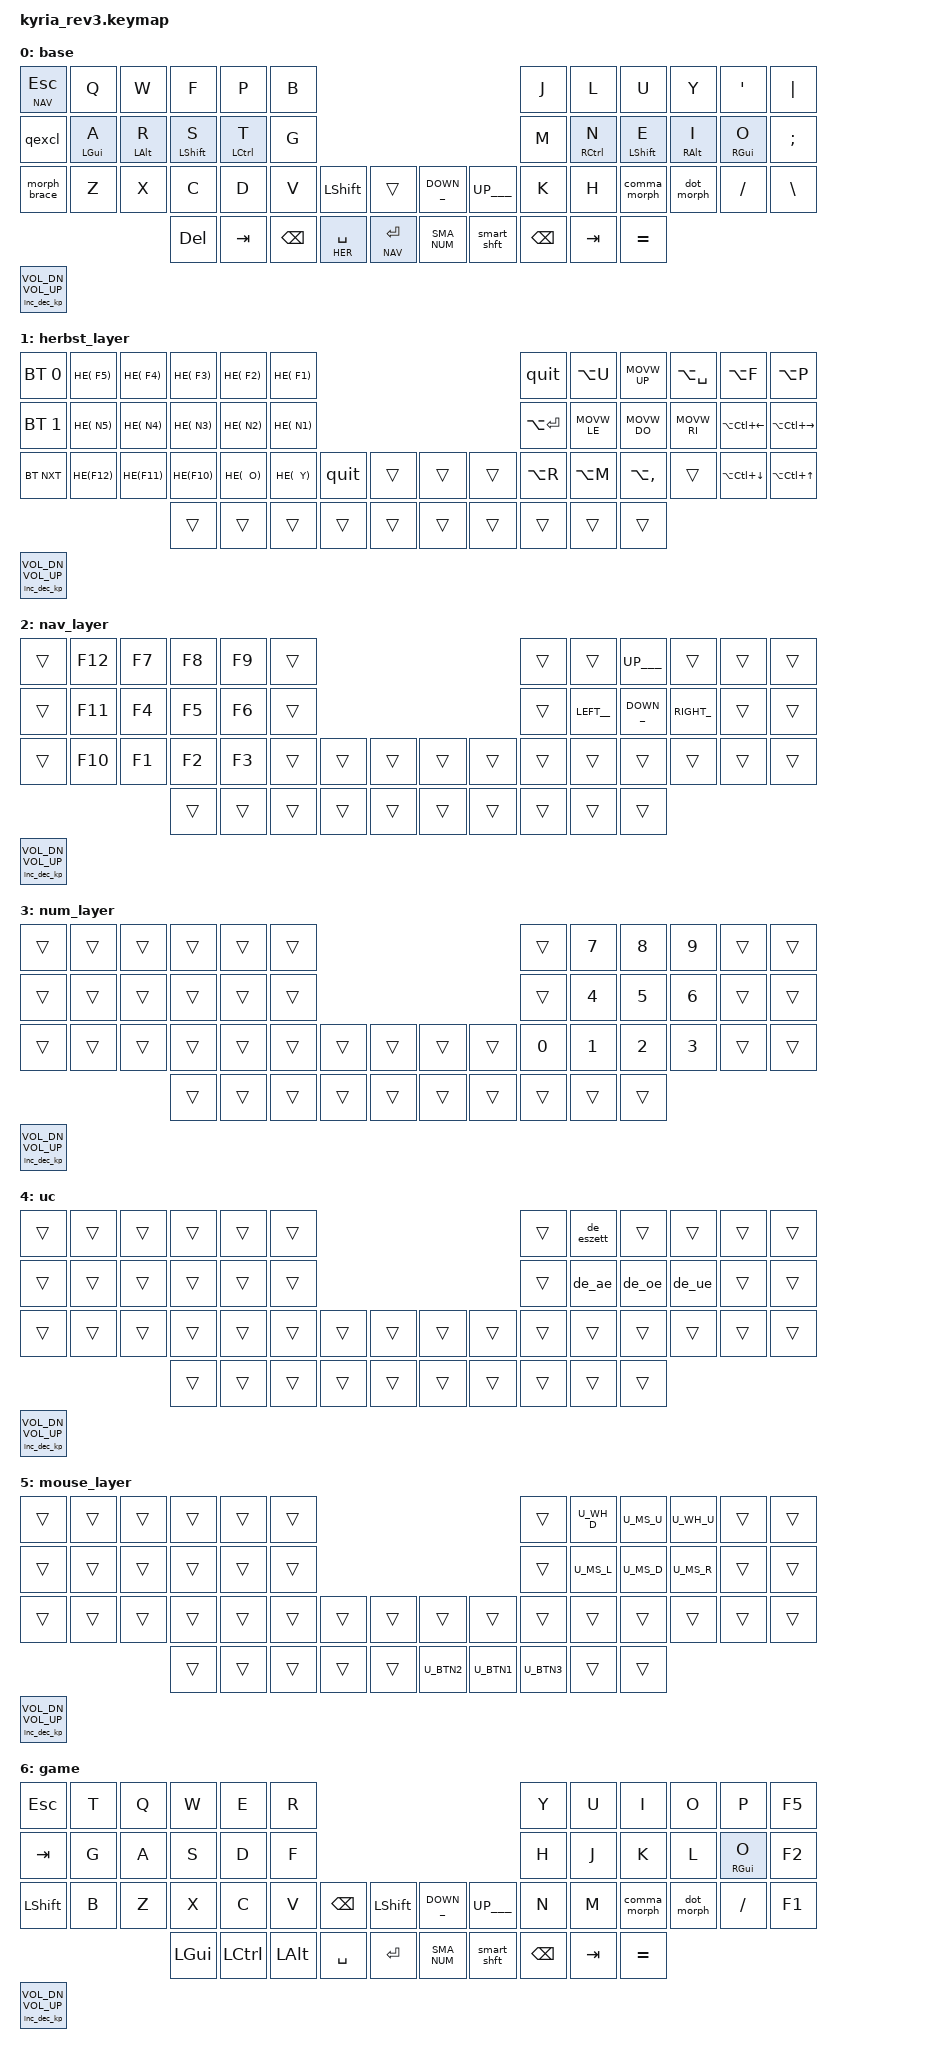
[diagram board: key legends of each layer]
#include <behaviors.dtsi>
#include <dt-bindings/zmk/keys.h>
#include <dt-bindings/zmk/bt.h>
#include <dt-bindings/zmk/outputs.h>
#define HOST_OS 1  // set to 1 for Linux, default is 0 (Windows)
#include "helper.h"
#include "german.dtsi"
#include "keypos_50keys.h"

#define DEF 0
#define HER 1
#define NAV 2
#define NUM 3
#define UC 4
#define MOUSE 5
#define GAME 6

// unused
#define FN 5
#define SYS 6

#include "combos.dtsi"  // requires layer aliases
#include "mouse.dtsi"

/* Global settings */

#define QUICK_TAP_MS 175

&sk {  // sticky-key config
    release-after-ms = <600>;  // release after 0.6s
    quick-release;             // no double capitalization when rolling keys
};

&sl {  // sticky-layer config
    ignore-modifiers;          // allow chording sticky mods & layers
};

&lt {  // layer-tap config
    flavor = "balanced";
    tapping-term-ms = <200>;
    quick-tap-ms = <QUICK_TAP_MS>;
};

&left_encoder { resolution = <2>; };
&right_encoder { resolution = <2>; };


/* Homerow mods */

#define KEYS_L LT0 LT1 LT2 LT3 LT4 LT5 LM0 LM1 LM2 LM3 LM4 RM5 LB0 LB1 LB2 LB3 LB4 LB5 // left-hand keys
#define KEYS_R RT0 RT1 RT2 RT3 RT4 RT5 RM0 RM1 RM2 RM3 RM4 RM5 RB0 RB1 RB2 RB3 RB4 LB5 // right-hand keys
#define THUMBS LH6 LH5 LH4 LH3 LH2 LH1 LH0 RH0 RH1 RH2 RH3 RH4 RH5 RH6

#define MAKE_HRM(NAME, HOLD, TAP, TRIGGER_POS) \
    ZMK_BEHAVIOR(NAME, hold_tap, \
        flavor = "balanced"; \
        tapping-term-ms = <280>; \
        quick-tap-ms = <QUICK_TAP_MS>; \
        global-quick-tap-ms = <150>; \
        bindings = <HOLD>, <TAP>; \
        hold-trigger-key-positions = <TRIGGER_POS>; \
        hold-trigger-on-release; \
    )
MAKE_HRM(hml, &kp, &kp, KEYS_R THUMBS)  // left-hand HRMs
MAKE_HRM(hmr, &kp, &kp, KEYS_L THUMBS)  // right-hand HRMs
MAKE_HRM(hml_repeat, &kp, &key_repeat, KEYS_R THUMBS)  // left-hand HRM for repeat combo

/* Nav cluster */

// long-tap action on hold, short-tap action on all interrupts
#define MT_CORE \
    flavor = "tap-preferred"; \
    tapping-term-ms = <220>; \
    quick-tap-ms = <220>; \
    hold-trigger-key-positions = <0>;

&mt { MT_CORE };
ZMK_BEHAVIOR(mt_home, hold_tap, bindings = <&masked_home>, <&kp>; MT_CORE)
ZMK_BEHAVIOR(mt_end,  hold_tap,  bindings = <&masked_end>, <&kp>; MT_CORE)

#define NAV_LEFT  &mt_home 0   LEFT    // tap: left  | long-tap: beginning of line
#define NAV_RIGHT &mt_end 0    RIGHT   // tap: right | long-tap: end       of line
#define NAV_UP    &mt PAGE_UP UP      // tap: up    | long-tap:
#define NAV_DOWN  &mt PAGE_DOWN  DOWN    // tap: down  | long-tap:
#define NAV_BSPC  &mt LC(BSPC) BSPC    // tap: bspc  | long-tap: delete word backward
#define NAV_DEL   &mt LC(DEL)  DEL     // tap: del   | long-tap: delete word forward

// mask CTRL when holding left/right to avoid accidental jumps to beginning/end of document
#define MASK_MODS(NAME, MODS, BINDING) \
    ZMK_BEHAVIOR(NAME, mod_morph, \
        bindings = <BINDING>, <BINDING>; \
        mods = <MODS>; \
    )
MASK_MODS(masked_home, (MOD_LCTL), &kp HOME)
MASK_MODS(masked_end,  (MOD_LCTL), &kp END)

/* Caps-word, num-word and smart-mouse */

// tap: sticky-shift | shift + tap/ double-tap: caps-word | hold: shift
ZMK_BEHAVIOR(smart_shft, mod_morph,
    bindings = <&sk LSHFT>, <&caps_word>;
    mods = <(MOD_LSFT)>;
)
&caps_word {  // mods deactivate caps-word, requires PR #1441
    /delete-property/ ignore-modifiers;
};

// tap: num-word | double-tap: sticky num-layer | hold: num-layer
#define SMART_NUM &smart_num NUM 0
ZMK_BEHAVIOR(smart_num, hold_tap,
    flavor = "balanced";
    tapping-term-ms = <200>;
    quick-tap-ms = <QUICK_TAP_MS>;
    bindings = <&mo>, <&num_dance>;
)
ZMK_BEHAVIOR(num_dance, tap_dance,
    tapping-term-ms = <200>;
    bindings = <&num_word>, <&sl NUM>;  // reverse this for sticky-num on single tap
)
&num_word {  // num-word, requires PR #1441
    layers = <NUM>;
};

// smart-mouse, requires PR #1366
ZMK_BEHAVIOR(smart_mouse, tri_state,
    bindings = <&tog MOUSE>, <&none>, <&tog MOUSE>;
    ignored-key-positions = <LT1 LT3 RT1 RT2 RT3 RM1 RM2 RM3 RH0 RH1>;
    ignored-layers = <MOUSE>;
)

/* Custom behaviors */

// Alt+Tab swapper, requires PR #1366
ZMK_BEHAVIOR(swapper, tri_state,
    bindings = <&kt LALT>, <&kp TAB>, <&kt LALT>;
    ignored-key-positions = <LT2>;
)

// Sticky layer + sticky shift (workaround for issue #1421)
ZMK_BEHAVIOR(sls, sticky_key,
    release-after-ms = <1000>;
    bindings = <&uc_shift>;
    ignore-modifiers;
)
ZMK_BEHAVIOR(uc_shift, macro,
    wait-ms = <0>;
    tap-ms = <1>;
    bindings = <&macro_press &mo UC &kp LSHFT>
             , <&macro_pause_for_release>
             , <&macro_release &mo UC &kp LSHFT>;
)

// tap: comma | shift + tap: semicolon | ctrl + shift + tap: <
ZMK_BEHAVIOR(comma_morph, mod_morph,
    mods = <(MOD_LSFT|MOD_RSFT)>;
    bindings = <&kp COMMA>, <&comma_inner_morph>;
)
ZMK_BEHAVIOR(comma_inner_morph, mod_morph,
    bindings = <&kp SEMICOLON>, <&kp LESS_THAN>;
    mods = <(MOD_LCTL|MOD_RCTL)>;
)

// tap: dot | shift + tap: colon | ctrl + shift + tap: >
ZMK_BEHAVIOR(dot_morph, mod_morph,
    bindings = <&kp DOT>, <&dot_inner_morph>;
    mods = <(MOD_LSFT|MOD_RSFT)>;
)
ZMK_BEHAVIOR(dot_inner_morph, mod_morph,
    bindings = <&kp COLON>, <&kp GREATER_THAN>;
    mods = <(MOD_LCTL|MOD_RCTL)>;
)

// tap: qmark | shift + tap: excl
ZMK_BEHAVIOR(qexcl, mod_morph,
    bindings = <&kp QMARK>, <&kp EXCL>;
    mods = <(MOD_LSFT|MOD_RSFT)>;
)

// tap: space | shift + tap: dot -> space -> sticky shift | hold: activate layer
ZMK_BEHAVIOR(lt_spc, hold_tap,
    flavor = "balanced";
    tapping-term-ms = <200>;
    quick-tap-ms = <QUICK_TAP_MS>;
    bindings = <&mo>, <&spc_morph>;
)
ZMK_BEHAVIOR(spc_morph, mod_morph,
    bindings = <&kp SPACE>, <&dot_spc>;
    mods = <(MOD_LSFT|MOD_RSFT)>;
)
ZMK_BEHAVIOR(dot_spc, macro,
    wait-ms = <0>;
    tap-ms = <5>;
    bindings = <&kp DOT &kp SPACE &sk LSHFT>;
)

// tap: backspace | lshft + tap: delete | rshft + tap: shift-delete
ZMK_BEHAVIOR(bs_del, mod_morph,
    bindings = <&kp BSPC>, <&kp DEL>;
    mods = <(MOD_LSFT|MOD_RSFT)>;
    keep-mods = <MOD_RSFT>;
)

// tap: copy | double-tap: cut
ZMK_BEHAVIOR(copy_cut, tap_dance,
    tapping-term-ms = <200>;
    bindings = <&kp LC(INS)>, <&kp LC(X)>;
)

// Windows sleep key
ZMK_BEHAVIOR(win_sleep, macro,
    wait-ms = <100>;
    tap-ms = <5>;
    bindings = <&kp LG(X) &kp U &kp S>;
)
// tap: CTRL-C | doubletap: ALT-SHIFT-C
ZMK_BEHAVIOR(quit, tap_dance,
    tapping-term-ms = <200>;
    bindings = <&kp LC(C)>, <&kp LA(LS(C))>;
)

ZMK_BEHAVIOR(morph_parent, mod_morph,
    bindings = <&kp LPAR>, <&kp RPAR>;
    mods = <(MOD_LSFT|MOD_RSFT)>;
)
ZMK_BEHAVIOR(morph_bracket, mod_morph,
  bindings = <&kp LBKT>, <&kp RBKT>;
  mods = <(MOD_LSFT|MOD_RSFT)>;
)
ZMK_BEHAVIOR(morph_brace, mod_morph,
  bindings = <&kp LBRC>, <&kp RBRC>;
  mods = <(MOD_LSFT|MOD_RSFT)>;
)

// misc aliases
#define CANCEL      &kp K_CANCEL             // cancel caps-word, num-word and smart-mouse
#define DSK_PREV    &hmr RSHFT LG(LC(LEFT))  // previous desktop
#define DSK_NEXT    &hmr LALT LG(LC(RIGHT))  // next     desktop
#define VOL_DOWN    &hmr LCTRL C_VOL_DN

/* Keymap */

#define _LEFT__ NAV_LEFT
#define __UP___ NAV_UP
#define _DOWN__ NAV_DOWN
#define _RIGHT_ NAV_RIGHT

#define _SPACE_ &lt HER SPACE
#define __TAB__ &kp TAB
#define _ENTER_ &lt NAV RET
#define _BKSPC_ &kp BACKSPACE
#define __DEL__ &kp DEL
#define __ESC__ &lt NAV ESC

#define ___A___ &hml LGUI A
#define ___B___ &kp B
#define ___C___ &kp C
#define ___D___ &kp D
#define ___E___ &hmr LSHFT E
#define ___F___ &kp F
#define ___G___ &kp G
#define ___H___ &kp H
#define ___I___ &hmr RALT I
#define ___J___ &kp J
#define ___K___ &kp K
#define ___L___ &kp L
#define ___M___ &kp M
#define ___N___ &hmr RCTRL N
#define ___O___ &hmr RGUI  O
#define ___P___ &kp P
#define ___Q___ &kp Q
#define ___R___ &hml LALT R
#define ___S___ &hml LSHFT S
#define ___T___ &hml LCTRL T
#define ___U___ &kp U
#define ___V___ &kp V
#define ___W___ &kp W
#define ___X___ &kp X
#define ___Y___ &kp Y
#define ___Z___ &kp Z

#define _COMMA_ &comma_morph
#define __DOT__ &dot_morph
#define _MINUS_ &kp MINUS
#define _SLASH_ &kp SLASH
#define _EXCL__ &kp EXCL
#define _QEXCL_ &qexcl


#define _SEMI__ &kp SEMI
#define _PIPE__ &kp PIPE
#define _EQUAL_ &kp EQUAL
#define _BSLH__ &kp BSLH
#define __SQT__ &kp SQT
#define __DEL__ &kp DEL

#define _PARENT &morph_parent
#define _BRACKT &morph_bracket
#define _BRACE_ &morph_brace

#define _LSHFT_ &kp LEFT_SHIFT
#define _LCTRL_ &kp LEFT_CONTROL
#define _LALT__ &kp LEFT_ALT
#define _LCMD__ &kp LEFT_COMMAND
#define _RSHFT_ &kp RIGHT_SHIFT
#define _RCTRL_ &kp RIGHT_CONTROL
#define _RALT__ &kp RIGHT_ALT
#define _RCMD__ &kp RIGHT_COMMAND

#define ___0___ &kp N0
#define ___1___ &kp N1
#define ___2___ &kp N2
#define ___3___ &kp N3
#define ___4___ &kp N4
#define ___5___ &kp N5
#define ___6___ &kp N6
#define ___7___ &kp N7
#define ___8___ &kp N8
#define ___9___ &kp N9

#define _BTCLR_ &bt BT_CLR
#define _BT_00_ &bt BT_SEL 0
#define _BT_01_ &bt BT_SEL 1
#define _BT_02_ &bt BT_SEL 2
#define _BT_PRV &bt BT_PRV
#define _BT_NXT &bt BT_NXT

#define _______ &trans

#define HE(X) &mt LS(LA(X)) LA(X)
#define LAUNCH_ &kp LA(U)
#define _SHELL_ &kp LA(RET)
#define _QUIT__ &quit
#define LAYOUT_ &kp LA(SPACE)
#define _FLOAT_ &kp LA(F)
#define _LOCK__ &kp LA(P)

#define MOVW_LE HE(LEFT)
#define MOVW_RI HE(RIGHT)
#define MOVW_UP HE(UP)
#define MOVW_DO HE(DOWN)

#define RSIZ_LE &kp LA(LC(LEFT))
#define RSIZ_RI &kp LA(LC(RIGHT))
#define RSIZ_UP &kp LA(LC(UP))
#define RSIZ_DO &kp LA(LC(DOWN))


#define SPLIT_H &kp LA(M)
#define SPLIT_V &kp LA(COMMA)
#define RES_SPL &kp LA(R)

#define SMA_NUM SMART_NUM
#define SMA_SHT &smart_shft

ZMK_LAYER(base,
	__ESC__ ___Q___ ___W___ ___F___ ___P___ ___B___                                  ___J___ ___L___ ___U___ ___Y___ __SQT__ _PIPE__
	_QEXCL_ ___A___ ___R___ ___S___ ___T___ ___G___                                  ___M___ ___N___ ___E___ ___I___ ___O___ _SEMI__
    _BRACE_ ___Z___ ___X___ ___C___ ___D___ ___V___ _LSHFT_ _______  _DOWN__ __UP___ ___K___ ___H___ _COMMA_ __DOT__ _SLASH_  _BSLH__
	                        __DEL__ __TAB__ _BKSPC_ _SPACE_ _ENTER_  SMA_NUM SMA_SHT _BKSPC_ __TAB__ _EQUAL_
    ,
    &inc_dec_kp C_VOL_DN C_VOL_UP
)

ZMK_LAYER(herbst_layer,
	_BT_00_ HE( F5) HE( F4) HE( F3) HE( F2) HE( F1)                                  _QUIT__ LAUNCH_ MOVW_UP LAYOUT_ _FLOAT_ _LOCK__
	_BT_01_ HE( N5) HE( N4) HE( N3) HE( N2) HE( N1)                                  _SHELL_ MOVW_LE MOVW_DO MOVW_RI RSIZ_LE RSIZ_RI
    _BT_NXT HE(F12) HE(F11) HE(F10) HE(  O) HE(  Y) _QUIT__ _______  _______ _______ RES_SPL SPLIT_H SPLIT_V _______ RSIZ_DO RSIZ_UP
                            _______ _______ _______ _______ _______  _______ _______ _______ _______ _______
    ,
    &inc_dec_kp C_VOL_DN C_VOL_UP
)

ZMK_LAYER(nav_layer,
	_______ &kp F12 &kp F7  &kp F8  &kp F9  _______                                  _______ _______ __UP___ _______ _______ _______
	_______ &kp F11 &kp F4  &kp F5  &kp F6  _______                                  _______ _LEFT__ _DOWN__ _RIGHT_ _______ _______
    _______ &kp F10 &kp F1  &kp F2  &kp F3  _______ _______ _______  _______ _______ _______ _______ _______ _______ _______ _______
	                        _______ _______ _______ _______ _______  _______ _______ _______ _______ _______
    ,
    &inc_dec_kp C_VOL_DN C_VOL_UP
)

ZMK_LAYER(num_layer,
	_______ _______ _______ _______ _______ _______                                  _______ ___7___ ___8___ ___9___ _______ _______
	_______ _______ _______ _______ _______ _______                                  _______ ___4___ ___5___ ___6___ _______ _______
    _______ _______ _______ _______ _______ _______ _______ _______  _______ _______ ___0___ ___1___ ___2___ ___3___ _______ _______
	                        _______ _______ _______ _______ _______  _______ _______ _______ _______ _______
    ,
    &inc_dec_kp C_VOL_DN C_VOL_UP
)

ZMK_LAYER(uc,
	_______ _______ _______ _______ _______ _______                                  _______ &de_eszett _______ _______ _______ _______
	_______ _______ _______ _______ _______ _______                                  _______ &de_ae  &de_oe  &de_ue  _______ _______
    _______ _______ _______ _______ _______ _______ _______ _______  _______ _______ _______ _______ _______ _______ _______ _______
	                        _______ _______ _______ _______ _______  _______ _______ _______ _______ _______
    ,
    &inc_dec_kp C_VOL_DN C_VOL_UP
)

ZMK_LAYER(mouse_layer,
	_______ _______ _______ _______ _______ _______                                  _______ U_WH_D  U_MS_U  U_WH_U  _______ _______
	_______ _______ _______ _______ _______ _______                                  _______ U_MS_L  U_MS_D  U_MS_R  _______ _______
    _______ _______ _______ _______ _______ _______ _______ _______  _______ _______ _______ _______ _______ _______ _______ _______
	                        _______ _______ _______ _______ _______  U_BTN2  U_BTN1  U_BTN3  _______ _______
    ,
    &inc_dec_kp C_VOL_DN C_VOL_UP
)

ZMK_LAYER(game,
  &kp ESC &kp T ___Q___ ___W___ &kp E   &kp R                                    ___Y___ ___U___ &kp I   &kp O   ___P___   &kp F5
	__TAB__ ___G___ &kp A   &kp S   &kp D   &kp F                                    ___H___ ___J___ ___K___ ___L___ ___O___ &kp F2
  &kp LEFT_SHIFT ___B___ ___Z___ ___X___ ___C___ ___V___ _BKSPC_ &kp LEFT_SHIFT  _DOWN__ __UP___ &kp N   ___M___ _COMMA_ __DOT__ _SLASH_ &kp F1
	                      &kp LGUI &kp LCTRL &kp LALT &kp SPACE &kp RET  SMA_NUM SMA_SHT _BKSPC_ __TAB__ _EQUAL_
    ,
    &inc_dec_kp C_VOL_DN C_VOL_UP
)


// _______ _______ _______ _______ _______ _______                                  _______ _______ _______ _______ _______ _______
// _______ _______ _______ _______ _______ _______                                  _______ _______ _______ _______ _______ _______
// _______ _______ _______ _______ _______ _______ _______ _______  _______ _______ _______ _______ _______ _______ _______ _______
//                         _______ _______ _______ _______ _______  _______ _______ _______ _______ _______
//	&trans &trans &trans &trans &trans &trans                                    &trans &trans &trans &trans &trans &trans
//	&trans &trans &trans &trans &trans &trans                                    &trans &trans &trans &trans &trans &trans
//  &trans &trans &trans &trans &trans &trans &trans &trans            &trans &trans &trans &trans &trans &trans &trans &trans
//                    &trans &trans &trans &trans &trans            &trans &trans &trans &trans &trans
